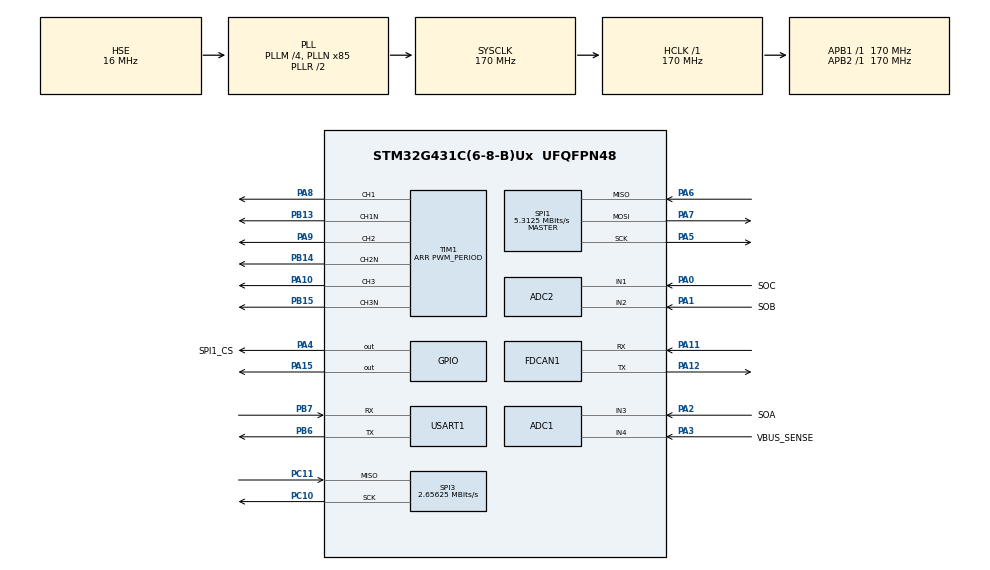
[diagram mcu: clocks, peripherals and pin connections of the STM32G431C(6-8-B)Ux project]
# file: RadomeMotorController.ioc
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ADC1.Channel-0\#ChannelRegularConversion=ADC_CHANNEL_3
ADC1.Channel-1\#ChannelRegularConversion=ADC_CHANNEL_4
ADC1.ClockPrescaler=ADC_CLOCK_ASYNC_DIV1
ADC1.ContinuousConvMode=ENABLE
ADC1.EOCSelection=ADC_EOC_SEQ_CONV
ADC1.ExternalTrigConv=ADC_EXTERNALTRIG_T1_TRGO
ADC1.NbrOfConversion=2
ADC1.NbrOfConversionFlag=1
ADC1.OffsetNumber-0\#ChannelRegularConversion=ADC_OFFSET_NONE
ADC1.OffsetNumber-1\#ChannelRegularConversion=ADC_OFFSET_NONE
ADC1.Overrun=ADC_OVR_DATA_OVERWRITTEN
ADC1.Rank-0\#ChannelRegularConversion=1
ADC1.Rank-1\#ChannelRegularConversion=2
ADC1.SamplingTime-0\#ChannelRegularConversion=ADC_SAMPLETIME_12CYCLES_5
ADC1.SamplingTime-1\#ChannelRegularConversion=ADC_SAMPLETIME_12CYCLES_5
ADC1.master=1
ADC2.Channel-0\#ChannelRegularConversion=ADC_CHANNEL_1
ADC2.Channel-1\#ChannelRegularConversion=ADC_CHANNEL_2
ADC2.ClockPrescaler=ADC_CLOCK_ASYNC_DIV1
ADC2.ContinuousConvMode=ENABLE
ADC2.EOCSelection=ADC_EOC_SEQ_CONV
ADC2.ExternalTrigConv=ADC_EXTERNALTRIG_T1_TRGO
ADC2.NbrOfConversion=2
ADC2.NbrOfConversionFlag=1
ADC2.OffsetNumber-0\#ChannelRegularConversion=ADC_OFFSET_NONE
ADC2.OffsetNumber-1\#ChannelRegularConversion=ADC_OFFSET_NONE
ADC2.Overrun=ADC_OVR_DATA_OVERWRITTEN
ADC2.Rank-0\#ChannelRegularConversion=1
ADC2.Rank-1\#ChannelRegularConversion=2
ADC2.SamplingTime-0\#ChannelRegularConversion=ADC_SAMPLETIME_12CYCLES_5
ADC2.SamplingTime-1\#ChannelRegularConversion=ADC_SAMPLETIME_12CYCLES_5
Dma.ADC1.0.Direction=DMA_PERIPH_TO_MEMORY
Dma.ADC1.0.EventEnable=DISABLE
Dma.ADC1.0.Instance=DMA1_Channel1
Dma.ADC1.0.MemDataAlignment=DMA_MDATAALIGN_HALFWORD
Dma.ADC1.0.MemInc=DMA_MINC_ENABLE
Dma.ADC1.0.Mode=DMA_CIRCULAR
Dma.ADC1.0.PeriphDataAlignment=DMA_PDATAALIGN_HALFWORD
Dma.ADC1.0.PeriphInc=DMA_PINC_DISABLE
Dma.ADC1.0.Polarity=HAL_DMAMUX_REQ_GEN_RISING
Dma.ADC1.0.Priority=DMA_PRIORITY_LOW
Dma.ADC1.0.RequestNumber=1
Dma.ADC1.0.SignalID=NONE
Dma.ADC1.0.SyncEnable=DISABLE
Dma.ADC1.0.SyncPolarity=HAL_DMAMUX_SYNC_NO_EVENT
Dma.ADC1.0.SyncRequestNumber=1
Dma.ADC1.0.SyncSignalID=NONE
Dma.ADC2.1.Direction=DMA_PERIPH_TO_MEMORY
Dma.ADC2.1.EventEnable=DISABLE
Dma.ADC2.1.Instance=DMA1_Channel2
Dma.ADC2.1.MemDataAlignment=DMA_MDATAALIGN_HALFWORD
Dma.ADC2.1.MemInc=DMA_MINC_ENABLE
Dma.ADC2.1.Mode=DMA_CIRCULAR
Dma.ADC2.1.PeriphDataAlignment=DMA_PDATAALIGN_HALFWORD
Dma.ADC2.1.PeriphInc=DMA_PINC_DISABLE
Dma.ADC2.1.Polarity=HAL_DMAMUX_REQ_GEN_RISING
Dma.ADC2.1.Priority=DMA_PRIORITY_LOW
Dma.ADC2.1.RequestNumber=1
Dma.ADC2.1.SignalID=NONE
Dma.ADC2.1.SyncEnable=DISABLE
Dma.ADC2.1.SyncPolarity=HAL_DMAMUX_SYNC_NO_EVENT
Dma.ADC2.1.SyncRequestNumber=1
Dma.ADC2.1.SyncSignalID=NONE
Dma.Request0=ADC1
Dma.Request1=ADC2
Dma.Request2=USART1_RX
Dma.Request3=SPI3_RX
Dma.SPI3_RX.3.Direction=DMA_PERIPH_TO_MEMORY
Dma.SPI3_RX.3.EventEnable=DISABLE
Dma.SPI3_RX.3.Instance=DMA1_Channel4
Dma.SPI3_RX.3.MemDataAlignment=DMA_MDATAALIGN_BYTE
Dma.SPI3_RX.3.MemInc=DMA_MINC_ENABLE
Dma.SPI3_RX.3.Mode=DMA_NORMAL
Dma.SPI3_RX.3.PeriphDataAlignment=DMA_PDATAALIGN_BYTE
Dma.SPI3_RX.3.PeriphInc=DMA_PINC_DISABLE
Dma.SPI3_RX.3.Polarity=HAL_DMAMUX_REQ_GEN_RISING
Dma.SPI3_RX.3.Priority=DMA_PRIORITY_LOW
Dma.SPI3_RX.3.RequestNumber=1
Dma.SPI3_RX.3.SignalID=NONE
Dma.SPI3_RX.3.SyncEnable=DISABLE
Dma.SPI3_RX.3.SyncPolarity=HAL_DMAMUX_SYNC_NO_EVENT
Dma.SPI3_RX.3.SyncRequestNumber=1
Dma.SPI3_RX.3.SyncSignalID=NONE
Dma.USART1_RX.2.Direction=DMA_PERIPH_TO_MEMORY
Dma.USART1_RX.2.EventEnable=DISABLE
Dma.USART1_RX.2.Instance=DMA1_Channel3
Dma.USART1_RX.2.MemDataAlignment=DMA_MDATAALIGN_BYTE
Dma.USART1_RX.2.MemInc=DMA_MINC_ENABLE
Dma.USART1_RX.2.Mode=DMA_CIRCULAR
Dma.USART1_RX.2.PeriphDataAlignment=DMA_PDATAALIGN_BYTE
Dma.USART1_RX.2.PeriphInc=DMA_PINC_DISABLE
Dma.USART1_RX.2.Polarity=HAL_DMAMUX_REQ_GEN_RISING
Dma.USART1_RX.2.Priority=DMA_PRIORITY_LOW
Dma.USART1_RX.2.RequestNumber=1
Dma.USART1_RX.2.SignalID=NONE
Dma.USART1_RX.2.SyncEnable=DISABLE
Dma.USART1_RX.2.SyncPolarity=HAL_DMAMUX_SYNC_NO_EVENT
Dma.USART1_RX.2.SyncRequestNumber=1
Dma.USART1_RX.2.SyncSignalID=NONE
FDCAN1.AutoRetransmission=ENABLE
FDCAN1.CalculateBaudRateNominal=125000
FDCAN1.CalculateTimeBitNominal=8000
FDCAN1.CalculateTimeQuantumNominal=800.0
FDCAN1.ClockDivider=FDCAN_CLOCK_DIV8
FDCAN1.DataPrescaler=17
FDCAN1.DataTimeSeg1=6
FDCAN1.DataTimeSeg2=3
FDCAN1.ExtFiltersNbr=2
FDCAN1.NominalPrescaler=17
FDCAN1.NominalTimeSeg1=6
FDCAN1.NominalTimeSeg2=3
FDCAN1.ProtocolException=ENABLE
FDCAN1.StdFiltersNbr=1
IWDG.Reload=2047
IWDG.Window=2047
Mcu.Family=STM32G4
Mcu.Name=STM32G431C(6-8-B)Ux
Mcu.Package=UFQFPN48
Mcu.UserConstants=ADC_SAMPLES,4;CLOCK_FREQ,170000000;DEAD_TIME,140;ADC_SEQ_LEN,2;PWM_ADC_TRIG,(ADC_CLK_SCALE * ADC_SEQ_LEN * ADC_SAMPLES / 2);PWM_FREQ,20000;ADC_CLK_SCALE,(3 * 25);PWM_PERIOD,(CLOCK_FREQ / (PWM_FREQ * 2));ADC_SW_OFFSET,180
NVIC.ADC1_2_IRQn=true\:0\:0\:false\:false\:true\:true\:true\:true
NVIC.DMA1_Channel1_IRQn=true\:0\:0\:false\:false\:true\:false\:true\:true
NVIC.DMA1_Channel2_IRQn=true\:0\:0\:false\:false\:true\:false\:true\:true
NVIC.DMA1_Channel3_IRQn=true\:0\:0\:false\:false\:true\:false\:true\:true
NVIC.DMA1_Channel4_IRQn=true\:0\:0\:false\:false\:true\:false\:true\:true
NVIC.FDCAN1_IT0_IRQn=true\:3\:0\:true\:false\:true\:true\:true\:true
NVIC.FDCAN1_IT1_IRQn=true\:0\:0\:false\:false\:true\:true\:true\:true
NVIC.PriorityGroup=NVIC_PRIORITYGROUP_4
NVIC.SPI3_IRQn=true\:0\:0\:false\:false\:true\:true\:true\:true
NVIC.TIM1_UP_TIM16_IRQn=true\:2\:0\:true\:false\:true\:true\:true\:true
NVIC.TIM7_IRQn=true\:4\:0\:true\:false\:true\:true\:true\:true
NVIC.USART1_IRQn=true\:7\:0\:true\:false\:true\:true\:true\:true
PA0.GPIO_Label=SOC
PA0.Mode=IN1-Single-Ended
PA0.Signal=ADC2_IN1
PA1.GPIO_Label=SOB
PA1.Mode=IN2-Single-Ended
PA1.Signal=ADC2_IN2
PA10.Signal=S_TIM1_CH3
PA11.Mode=FDCAN_Activate
PA11.Signal=FDCAN1_RX
PA12.Mode=FDCAN_Activate
PA12.Signal=FDCAN1_TX
PA13.Mode=Serial_Wire
PA13.Signal=SYS_JTMS-SWDIO
PA14.Mode=Serial_Wire
PA14.Signal=SYS_JTCK-SWCLK
PA15.Signal=GPIO_Output
PA2.GPIO_Label=SOA
PA2.Mode=IN3-Single-Ended
PA2.Signal=ADC1_IN3
PA3.GPIO_Label=VBUS_SENSE
PA3.Mode=IN4-Single-Ended
PA3.Signal=ADC1_IN4
PA4.GPIO_Label=SPI1_CS
PA4.Signal=GPIO_Output
PA5.Mode=Full_Duplex_Master
PA5.Signal=SPI1_SCK
PA6.Mode=Full_Duplex_Master
PA6.Signal=SPI1_MISO
PA7.Mode=Full_Duplex_Master
PA7.Signal=SPI1_MOSI
PA8.Signal=S_TIM1_CH1
PA9.Signal=S_TIM1_CH2
PB13.Mode=PWM Generation1 CH1 CH1N
PB13.Signal=TIM1_CH1N
PB14.Mode=PWM Generation2 CH2 CH2N
PB14.Signal=TIM1_CH2N
PB15.Mode=PWM Generation3 CH3 CH3N
PB15.Signal=TIM1_CH3N
PB6.Mode=Asynchronous
PB6.Signal=USART1_TX
PB7.Mode=Asynchronous
PB7.Signal=USART1_RX
PC10.Mode=RX_Only_Simplex_Unidirect_Master
PC10.Signal=SPI3_SCK
PC11.Mode=RX_Only_Simplex_Unidirect_Master
PC11.Signal=SPI3_MISO
PF0-OSC_IN.Mode=HSE-External-Oscillator
PF0-OSC_IN.Signal=RCC_OSC_IN
PF1-OSC_OUT.Mode=HSE-External-Oscillator
PF1-OSC_OUT.Signal=RCC_OSC_OUT
ProjectManager.HeapSize=0x200
ProjectManager.StackSize=0x400
ProjectManager.TargetToolchain=STM32CubeIDE
RCC.ADC12CLockSelection=RCC_ADC12CLKSOURCE_PLL
RCC.ADC12Freq_Value=56666666.666666664
RCC.AHBFreq_Value=170000000
RCC.APB1Freq_Value=170000000
RCC.APB1TimFreq_Value=170000000
RCC.APB2Freq_Value=170000000
RCC.APB2TimFreq_Value=170000000
RCC.CK48CLockSelection=RCC_USBCLKSOURCE_HSI48
RCC.CortexFreq_Value=170000000
RCC.EXTERNAL_CLOCK_VALUE=12288000
RCC.HCLKFreq_Value=170000000
RCC.HSE_VALUE=16000000
RCC.HSI48_VALUE=48000000
RCC.HSI_VALUE=16000000
RCC.LSE_VALUE=32768
RCC.PLLM=RCC_PLLM_DIV4
RCC.PLLN=85
RCC.PLLP=RCC_PLLP_DIV6
RCC.PLLQ=RCC_PLLQ_DIV8
RCC.PLLSourceVirtual=RCC_PLLSOURCE_HSE
RCC.PREFETCH_ENABLE=1
RCC.RTCClockSelection=RCC_RTCCLKSOURCE_LSE
RCC.SYSCLKFreq_VALUE=170000000
RCC.SYSCLKSource=RCC_SYSCLKSOURCE_PLLCLK
RCC.USART1CLockSelection=RCC_USART1CLKSOURCE_SYSCLK
RCC.USBFreq_Value=48000000
RCC.VCOOutputFreq_Value=340000000
SH.S_TIM1_CH1.0=TIM1_CH1,PWM Generation1 CH1 CH1N
SH.S_TIM1_CH2.0=TIM1_CH2,PWM Generation2 CH2 CH2N
SH.S_TIM1_CH3.0=TIM1_CH3,PWM Generation3 CH3 CH3N
SPI1.BaudRatePrescaler=SPI_BAUDRATEPRESCALER_32
SPI1.CLKPhase=SPI_PHASE_2EDGE
SPI1.CalculateBaudRate=5.3125 MBits/s
SPI1.DataSize=SPI_DATASIZE_8BIT
SPI1.Direction=SPI_DIRECTION_2LINES
SPI1.Mode=SPI_MODE_MASTER
SPI1.TIMode=SPI_TIMODE_DISABLE
SPI1.VirtualType=VM_MASTER
SPI3.BaudRatePrescaler=SPI_BAUDRATEPRESCALER_64
SPI3.CLKPhase=SPI_PHASE_1EDGE
SPI3.CLKPolarity=SPI_POLARITY_HIGH
SPI3.CalculateBaudRate=2.65625 MBits/s
SPI3.DataSize=SPI_DATASIZE_8BIT
SPI3.Direction=SPI_DIRECTION_2LINES_RXONLY
SPI3.Mode=SPI_MODE_MASTER
SPI3.VirtualType=VM_MASTER
TIM1.Channel-PWM\ Generation1\ CH1\ CH1N=TIM_CHANNEL_1
TIM1.Channel-PWM\ Generation2\ CH2\ CH2N=TIM_CHANNEL_2
TIM1.Channel-PWM\ Generation3\ CH3\ CH3N=TIM_CHANNEL_3
TIM1.Channel-PWM\ Generation4\ No\ Output=TIM_CHANNEL_4
TIM1.CounterMode=TIM_COUNTERMODE_CENTERALIGNED2
TIM1.DeadTime=DEAD_TIME
TIM1.PeriodNoDither=PWM_PERIOD
TIM1.PulseNoDither_1=PWM_PERIOD/2
TIM1.PulseNoDither_2=PWM_PERIOD/2
TIM1.PulseNoDither_3=PWM_PERIOD/2
TIM1.PulseNoDither_4=PWM_ADC_TRIG
TIM1.TIM_MasterOutputTrigger=TIM_TRGO_OC4REF
TIM7.AutoReloadPreload=TIM_AUTORELOAD_PRELOAD_ENABLE
TIM7.PeriodNoDither=499
TIM7.Prescaler=169
TIM7.TIM_MasterOutputTrigger=TIM_TRGO_UPDATE
USART1.VirtualMode-Asynchronous=VM_ASYNC
VP_CORDIC_VS_CORDIC.Mode=CORDIC_Activate
VP_IWDG_VS_IWDG.Mode=IWDG_Activate
VP_SYS_VS_DBSignals.Mode=DisableDeadBatterySignals
VP_TIM1_VS_no_output4.Mode=PWM Generation4 No Output
VP_TIM6_VS_ClockSourceINT.Mode=Enable_Timer
VP_TIM7_VS_ClockSourceINT.Mode=Enable_Timer
board=custom

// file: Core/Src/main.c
/* USER CODE BEGIN Header */
/**
  ******************************************************************************
  * @file           : main.c
  * @brief          : Main program body
  ******************************************************************************
  * @attention
  *
  * Copyright (c) 2022 STMicroelectronics.
  * All rights reserved.
  *
  * This software is licensed under terms that can be found in the LICENSE file
  * in the root directory of this software component.
  * If no LICENSE file comes with this software, it is provided AS-IS.
  *
  ******************************************************************************
  */
/* USER CODE END Header */
#include "main.h"

/* USER CODE BEGIN Includes */
#include <loop.h>

/* USER CODE END Includes */

ADC_HandleTypeDef hadc1;
ADC_HandleTypeDef hadc2;
DMA_HandleTypeDef hdma_adc1;
DMA_HandleTypeDef hdma_adc2;

CORDIC_HandleTypeDef hcordic;

FDCAN_HandleTypeDef hfdcan1;

IWDG_HandleTypeDef hiwdg;

SPI_HandleTypeDef hspi1;
SPI_HandleTypeDef hspi3;
DMA_HandleTypeDef hdma_spi3_rx;

TIM_HandleTypeDef htim1;
TIM_HandleTypeDef htim6;
TIM_HandleTypeDef htim7;

UART_HandleTypeDef huart1;
DMA_HandleTypeDef hdma_usart1_rx;

void SystemClock_Config(void);
static void MX_GPIO_Init(void);
static void MX_DMA_Init(void);
static void MX_ADC2_Init(void);
static void MX_TIM1_Init(void);
static void MX_TIM6_Init(void);
static void MX_ADC1_Init(void);
static void MX_USART1_UART_Init(void);
static void MX_CORDIC_Init(void);
static void MX_FDCAN1_Init(void);
static void MX_SPI3_Init(void);
static void MX_SPI1_Init(void);
static void MX_TIM7_Init(void);
static void MX_IWDG_Init(void);

int main(void)
{

  /* MCU Configuration--------------------------------------------------------*/

  /* Reset of all peripherals, Initializes the Flash interface and the Systick. */
  HAL_Init();

  /* Configure the system clock */
  SystemClock_Config();

  /* Initialize all configured peripherals */
  MX_GPIO_Init();
  MX_DMA_Init();
  MX_TIM1_Init();
  MX_TIM6_Init();
  MX_USART1_UART_Init();
  MX_CORDIC_Init();
  MX_FDCAN1_Init();
  MX_SPI3_Init();
  MX_SPI1_Init();
  MX_TIM7_Init();
  /* USER CODE BEGIN 2 */
  MX_ADC1_Init();
  MX_ADC2_Init();
  setup();

  MX_IWDG_Init();

  /* USER CODE END 2 */

  /* Infinite loop */
  while (1)
  {

    /* USER CODE BEGIN 3 */
	  loop();

  }
  /* USER CODE END 3 */
}

void SystemClock_Config(void)
{
  RCC_OscInitTypeDef RCC_OscInitStruct = {0};
  RCC_ClkInitTypeDef RCC_ClkInitStruct = {0};

  /** Configure the main internal regulator output voltage
  */
  HAL_PWREx_ControlVoltageScaling(PWR_REGULATOR_VOLTAGE_SCALE1_BOOST);

  /** Initializes the RCC Oscillators according to the specified parameters
  * in the RCC_OscInitTypeDef structure.
  */
  RCC_OscInitStruct.OscillatorType = RCC_OSCILLATORTYPE_LSI|RCC_OSCILLATORTYPE_HSE;
  RCC_OscInitStruct.HSEState = RCC_HSE_ON;
  RCC_OscInitStruct.LSIState = RCC_LSI_ON;
  RCC_OscInitStruct.PLL.PLLState = RCC_PLL_ON;
  RCC_OscInitStruct.PLL.PLLSource = RCC_PLLSOURCE_HSE;
  RCC_OscInitStruct.PLL.PLLM = RCC_PLLM_DIV4;
  RCC_OscInitStruct.PLL.PLLN = 85;
  RCC_OscInitStruct.PLL.PLLP = RCC_PLLP_DIV6;
  RCC_OscInitStruct.PLL.PLLQ = RCC_PLLQ_DIV8;
  RCC_OscInitStruct.PLL.PLLR = RCC_PLLR_DIV2;
  if (HAL_RCC_OscConfig(&RCC_OscInitStruct) != HAL_OK)
  {
    Error_Handler();
  }

  /** Initializes the CPU, AHB and APB buses clocks
  */
  RCC_ClkInitStruct.ClockType = RCC_CLOCKTYPE_HCLK|RCC_CLOCKTYPE_SYSCLK
                              |RCC_CLOCKTYPE_PCLK1|RCC_CLOCKTYPE_PCLK2;
  RCC_ClkInitStruct.SYSCLKSource = RCC_SYSCLKSOURCE_PLLCLK;
  RCC_ClkInitStruct.AHBCLKDivider = RCC_SYSCLK_DIV1;
  RCC_ClkInitStruct.APB1CLKDivider = RCC_HCLK_DIV1;
  RCC_ClkInitStruct.APB2CLKDivider = RCC_HCLK_DIV1;

  if (HAL_RCC_ClockConfig(&RCC_ClkInitStruct, FLASH_LATENCY_4) != HAL_OK)
  {
    Error_Handler();
  }
}

static void MX_ADC1_Init(void)
{

  ADC_MultiModeTypeDef multimode = {0};
  ADC_ChannelConfTypeDef sConfig = {0};

  /** Common config
  */
  hadc1.Instance = ADC1;
  hadc1.Init.ClockPrescaler = ADC_CLOCK_ASYNC_DIV1;
  hadc1.Init.Resolution = ADC_RESOLUTION_12B;
  hadc1.Init.DataAlign = ADC_DATAALIGN_RIGHT;
  hadc1.Init.GainCompensation = 0;
  hadc1.Init.ScanConvMode = ADC_SCAN_ENABLE;
  hadc1.Init.EOCSelection = ADC_EOC_SEQ_CONV;
  hadc1.Init.LowPowerAutoWait = DISABLE;
  hadc1.Init.ContinuousConvMode = ENABLE;
  hadc1.Init.NbrOfConversion = 2;
  hadc1.Init.DiscontinuousConvMode = DISABLE;
  hadc1.Init.ExternalTrigConv = ADC_EXTERNALTRIG_T1_TRGO;
  hadc1.Init.ExternalTrigConvEdge = ADC_EXTERNALTRIGCONVEDGE_RISING;
  hadc1.Init.DMAContinuousRequests = DISABLE;
  hadc1.Init.Overrun = ADC_OVR_DATA_OVERWRITTEN;
  hadc1.Init.OversamplingMode = DISABLE;
  if (HAL_ADC_Init(&hadc1) != HAL_OK)
  {
    Error_Handler();
  }

  /** Configure the ADC multi-mode
  */
  multimode.Mode = ADC_MODE_INDEPENDENT;
  if (HAL_ADCEx_MultiModeConfigChannel(&hadc1, &multimode) != HAL_OK)
  {
    Error_Handler();
  }

  /** Configure Regular Channel
  */
  sConfig.Channel = ADC_CHANNEL_3;
  sConfig.Rank = ADC_REGULAR_RANK_1;
  sConfig.SamplingTime = ADC_SAMPLETIME_12CYCLES_5;
  sConfig.SingleDiff = ADC_SINGLE_ENDED;
  sConfig.OffsetNumber = ADC_OFFSET_NONE;
  sConfig.Offset = 0;
  if (HAL_ADC_ConfigChannel(&hadc1, &sConfig) != HAL_OK)
  {
    Error_Handler();
  }

  /** Configure Regular Channel
  */
  sConfig.Channel = ADC_CHANNEL_4;
  sConfig.Rank = ADC_REGULAR_RANK_2;
  if (HAL_ADC_ConfigChannel(&hadc1, &sConfig) != HAL_OK)
  {
    Error_Handler();
  }

}

static void MX_ADC2_Init(void)
{

  ADC_ChannelConfTypeDef sConfig = {0};

  /** Common config
  */
  hadc2.Instance = ADC2;
  hadc2.Init.ClockPrescaler = ADC_CLOCK_ASYNC_DIV1;
  hadc2.Init.Resolution = ADC_RESOLUTION_12B;
  hadc2.Init.DataAlign = ADC_DATAALIGN_RIGHT;
  hadc2.Init.GainCompensation = 0;
  hadc2.Init.ScanConvMode = ADC_SCAN_ENABLE;
  hadc2.Init.EOCSelection = ADC_EOC_SEQ_CONV;
  hadc2.Init.LowPowerAutoWait = DISABLE;
  hadc2.Init.ContinuousConvMode = ENABLE;
  hadc2.Init.NbrOfConversion = 2;
  hadc2.Init.DiscontinuousConvMode = DISABLE;
  hadc2.Init.ExternalTrigConv = ADC_EXTERNALTRIG_T1_TRGO;
  hadc2.Init.ExternalTrigConvEdge = ADC_EXTERNALTRIGCONVEDGE_RISING;
  hadc2.Init.DMAContinuousRequests = DISABLE;
  hadc2.Init.Overrun = ADC_OVR_DATA_OVERWRITTEN;
  hadc2.Init.OversamplingMode = DISABLE;
  if (HAL_ADC_Init(&hadc2) != HAL_OK)
  {
    Error_Handler();
  }

  /** Configure Regular Channel
  */
  sConfig.Channel = ADC_CHANNEL_1;
  sConfig.Rank = ADC_REGULAR_RANK_1;
  sConfig.SamplingTime = ADC_SAMPLETIME_12CYCLES_5;
  sConfig.SingleDiff = ADC_SINGLE_ENDED;
  sConfig.OffsetNumber = ADC_OFFSET_NONE;
  sConfig.Offset = 0;
  if (HAL_ADC_ConfigChannel(&hadc2, &sConfig) != HAL_OK)
  {
    Error_Handler();
  }

  /** Configure Regular Channel
  */
  sConfig.Channel = ADC_CHANNEL_2;
  sConfig.Rank = ADC_REGULAR_RANK_2;
  if (HAL_ADC_ConfigChannel(&hadc2, &sConfig) != HAL_OK)
  {
    Error_Handler();
  }

}

static void MX_CORDIC_Init(void)
{

  hcordic.Instance = CORDIC;
  if (HAL_CORDIC_Init(&hcordic) != HAL_OK)
  {
    Error_Handler();
  }

}

static void MX_FDCAN1_Init(void)
{

  hfdcan1.Instance = FDCAN1;
  hfdcan1.Init.ClockDivider = FDCAN_CLOCK_DIV8;
  hfdcan1.Init.FrameFormat = FDCAN_FRAME_CLASSIC;
  hfdcan1.Init.Mode = FDCAN_MODE_NORMAL;
  hfdcan1.Init.AutoRetransmission = ENABLE;
  hfdcan1.Init.TransmitPause = DISABLE;
  hfdcan1.Init.ProtocolException = ENABLE;
  hfdcan1.Init.NominalPrescaler = 17;
  hfdcan1.Init.NominalSyncJumpWidth = 1;
  hfdcan1.Init.NominalTimeSeg1 = 6;
  hfdcan1.Init.NominalTimeSeg2 = 3;
  hfdcan1.Init.DataPrescaler = 17;
  hfdcan1.Init.DataSyncJumpWidth = 1;
  hfdcan1.Init.DataTimeSeg1 = 6;
  hfdcan1.Init.DataTimeSeg2 = 3;
  hfdcan1.Init.StdFiltersNbr = 1;
  hfdcan1.Init.ExtFiltersNbr = 2;
  hfdcan1.Init.TxFifoQueueMode = FDCAN_TX_FIFO_OPERATION;
  if (HAL_FDCAN_Init(&hfdcan1) != HAL_OK)
  {
    Error_Handler();
  }

}

static void MX_IWDG_Init(void)
{

  hiwdg.Instance = IWDG;
  hiwdg.Init.Prescaler = IWDG_PRESCALER_4;
  hiwdg.Init.Window = 2047;
  hiwdg.Init.Reload = 2047;
  if (HAL_IWDG_Init(&hiwdg) != HAL_OK)
  {
    Error_Handler();
  }

}

static void MX_SPI1_Init(void)
{

  /* SPI1 parameter configuration*/
  hspi1.Instance = SPI1;
  hspi1.Init.Mode = SPI_MODE_MASTER;
  hspi1.Init.Direction = SPI_DIRECTION_2LINES;
  hspi1.Init.DataSize = SPI_DATASIZE_8BIT;
  hspi1.Init.CLKPolarity = SPI_POLARITY_LOW;
  hspi1.Init.CLKPhase = SPI_PHASE_2EDGE;
  hspi1.Init.NSS = SPI_NSS_SOFT;
  hspi1.Init.BaudRatePrescaler = SPI_BAUDRATEPRESCALER_32;
  hspi1.Init.FirstBit = SPI_FIRSTBIT_MSB;
  hspi1.Init.TIMode = SPI_TIMODE_DISABLE;
  hspi1.Init.CRCCalculation = SPI_CRCCALCULATION_DISABLE;
  hspi1.Init.CRCPolynomial = 7;
  hspi1.Init.CRCLength = SPI_CRC_LENGTH_DATASIZE;
  hspi1.Init.NSSPMode = SPI_NSS_PULSE_DISABLE;
  if (HAL_SPI_Init(&hspi1) != HAL_OK)
  {
    Error_Handler();
  }

}

static void MX_SPI3_Init(void)
{

  /* SPI3 parameter configuration*/
  hspi3.Instance = SPI3;
  hspi3.Init.Mode = SPI_MODE_MASTER;
  hspi3.Init.Direction = SPI_DIRECTION_2LINES_RXONLY;
  hspi3.Init.DataSize = SPI_DATASIZE_8BIT;
  hspi3.Init.CLKPolarity = SPI_POLARITY_HIGH;
  hspi3.Init.CLKPhase = SPI_PHASE_1EDGE;
  hspi3.Init.NSS = SPI_NSS_SOFT;
  hspi3.Init.BaudRatePrescaler = SPI_BAUDRATEPRESCALER_64;
  hspi3.Init.FirstBit = SPI_FIRSTBIT_MSB;
  hspi3.Init.TIMode = SPI_TIMODE_DISABLE;
  hspi3.Init.CRCCalculation = SPI_CRCCALCULATION_DISABLE;
  hspi3.Init.CRCPolynomial = 7;
  hspi3.Init.CRCLength = SPI_CRC_LENGTH_DATASIZE;
  hspi3.Init.NSSPMode = SPI_NSS_PULSE_ENABLE;
  if (HAL_SPI_Init(&hspi3) != HAL_OK)
  {
    Error_Handler();
  }

}

static void MX_TIM1_Init(void)
{

  TIM_MasterConfigTypeDef sMasterConfig = {0};
  TIM_OC_InitTypeDef sConfigOC = {0};
  TIM_BreakDeadTimeConfigTypeDef sBreakDeadTimeConfig = {0};

  htim1.Instance = TIM1;
  htim1.Init.Prescaler = 0;
  htim1.Init.CounterMode = TIM_COUNTERMODE_CENTERALIGNED2;
  htim1.Init.Period = 4250;
  htim1.Init.ClockDivision = TIM_CLOCKDIVISION_DIV1;
  htim1.Init.RepetitionCounter = 0;
  htim1.Init.AutoReloadPreload = TIM_AUTORELOAD_PRELOAD_DISABLE;
  if (HAL_TIM_PWM_Init(&htim1) != HAL_OK)
  {
    Error_Handler();
  }
  sMasterConfig.MasterOutputTrigger = TIM_TRGO_OC4REF;
  sMasterConfig.MasterOutputTrigger2 = TIM_TRGO2_RESET;
  sMasterConfig.MasterSlaveMode = TIM_MASTERSLAVEMODE_DISABLE;
  if (HAL_TIMEx_MasterConfigSynchronization(&htim1, &sMasterConfig) != HAL_OK)
  {
    Error_Handler();
  }
  sConfigOC.OCMode = TIM_OCMODE_PWM1;
  sConfigOC.Pulse = 2125;
  sConfigOC.OCPolarity = TIM_OCPOLARITY_HIGH;
  sConfigOC.OCNPolarity = TIM_OCNPOLARITY_HIGH;
  sConfigOC.OCFastMode = TIM_OCFAST_DISABLE;
  sConfigOC.OCIdleState = TIM_OCIDLESTATE_RESET;
  sConfigOC.OCNIdleState = TIM_OCNIDLESTATE_RESET;
  if (HAL_TIM_PWM_ConfigChannel(&htim1, &sConfigOC, TIM_CHANNEL_1) != HAL_OK)
  {
    Error_Handler();
  }
  if (HAL_TIM_PWM_ConfigChannel(&htim1, &sConfigOC, TIM_CHANNEL_2) != HAL_OK)
  {
    Error_Handler();
  }
  if (HAL_TIM_PWM_ConfigChannel(&htim1, &sConfigOC, TIM_CHANNEL_3) != HAL_OK)
  {
    Error_Handler();
  }
  sConfigOC.Pulse = 300;
  if (HAL_TIM_PWM_ConfigChannel(&htim1, &sConfigOC, TIM_CHANNEL_4) != HAL_OK)
  {
    Error_Handler();
  }
  sBreakDeadTimeConfig.OffStateRunMode = TIM_OSSR_DISABLE;
  sBreakDeadTimeConfig.OffStateIDLEMode = TIM_OSSI_DISABLE;
  sBreakDeadTimeConfig.LockLevel = TIM_LOCKLEVEL_OFF;
  sBreakDeadTimeConfig.DeadTime = DEAD_TIME;
  sBreakDeadTimeConfig.BreakState = TIM_BREAK_DISABLE;
  sBreakDeadTimeConfig.BreakPolarity = TIM_BREAKPOLARITY_HIGH;
  sBreakDeadTimeConfig.BreakFilter = 0;
  sBreakDeadTimeConfig.BreakAFMode = TIM_BREAK_AFMODE_INPUT;
  sBreakDeadTimeConfig.Break2State = TIM_BREAK2_DISABLE;
  sBreakDeadTimeConfig.Break2Polarity = TIM_BREAK2POLARITY_HIGH;
  sBreakDeadTimeConfig.Break2Filter = 0;
  sBreakDeadTimeConfig.Break2AFMode = TIM_BREAK_AFMODE_INPUT;
  sBreakDeadTimeConfig.AutomaticOutput = TIM_AUTOMATICOUTPUT_DISABLE;
  if (HAL_TIMEx_ConfigBreakDeadTime(&htim1, &sBreakDeadTimeConfig) != HAL_OK)
  {
    Error_Handler();
  }
  HAL_TIM_MspPostInit(&htim1);

}

static void MX_TIM6_Init(void)
{

  TIM_MasterConfigTypeDef sMasterConfig = {0};

  htim6.Instance = TIM6;
  htim6.Init.Prescaler = 0;
  htim6.Init.CounterMode = TIM_COUNTERMODE_UP;
  htim6.Init.Period = 65535;
  htim6.Init.AutoReloadPreload = TIM_AUTORELOAD_PRELOAD_DISABLE;
  if (HAL_TIM_Base_Init(&htim6) != HAL_OK)
  {
    Error_Handler();
  }
  sMasterConfig.MasterOutputTrigger = TIM_TRGO_RESET;
  sMasterConfig.MasterSlaveMode = TIM_MASTERSLAVEMODE_DISABLE;
  if (HAL_TIMEx_MasterConfigSynchronization(&htim6, &sMasterConfig) != HAL_OK)
  {
    Error_Handler();
  }

}

static void MX_TIM7_Init(void)
{

  TIM_MasterConfigTypeDef sMasterConfig = {0};

  htim7.Instance = TIM7;
  htim7.Init.Prescaler = 169;
  htim7.Init.CounterMode = TIM_COUNTERMODE_UP;
  htim7.Init.Period = 499;
  htim7.Init.AutoReloadPreload = TIM_AUTORELOAD_PRELOAD_ENABLE;
  if (HAL_TIM_Base_Init(&htim7) != HAL_OK)
  {
    Error_Handler();
  }
  sMasterConfig.MasterOutputTrigger = TIM_TRGO_UPDATE;
  sMasterConfig.MasterSlaveMode = TIM_MASTERSLAVEMODE_DISABLE;
  if (HAL_TIMEx_MasterConfigSynchronization(&htim7, &sMasterConfig) != HAL_OK)
  {
    Error_Handler();
  }

}

static void MX_USART1_UART_Init(void)
{

  huart1.Instance = USART1;
  huart1.Init.BaudRate = 115200;
  huart1.Init.WordLength = UART_WORDLENGTH_8B;
  huart1.Init.StopBits = UART_STOPBITS_1;
  huart1.Init.Parity = UART_PARITY_NONE;
  huart1.Init.Mode = UART_MODE_TX_RX;
  huart1.Init.HwFlowCtl = UART_HWCONTROL_NONE;
  huart1.Init.OverSampling = UART_OVERSAMPLING_16;
  huart1.Init.OneBitSampling = UART_ONE_BIT_SAMPLE_DISABLE;
  huart1.Init.ClockPrescaler = UART_PRESCALER_DIV1;
  huart1.AdvancedInit.AdvFeatureInit = UART_ADVFEATURE_NO_INIT;
  if (HAL_UART_Init(&huart1) != HAL_OK)
  {
    Error_Handler();
  }
  if (HAL_UARTEx_SetTxFifoThreshold(&huart1, UART_TXFIFO_THRESHOLD_1_8) != HAL_OK)
  {
    Error_Handler();
  }
  if (HAL_UARTEx_SetRxFifoThreshold(&huart1, UART_RXFIFO_THRESHOLD_1_8) != HAL_OK)
  {
    Error_Handler();
  }
  if (HAL_UARTEx_DisableFifoMode(&huart1) != HAL_OK)
  {
    Error_Handler();
  }

}

static void MX_DMA_Init(void)
{

  /* DMA controller clock enable */
  __HAL_RCC_DMAMUX1_CLK_ENABLE();
  __HAL_RCC_DMA1_CLK_ENABLE();

  /* DMA interrupt init */
  /* DMA1_Channel1_IRQn interrupt configuration */
  HAL_NVIC_SetPriority(DMA1_Channel1_IRQn, 0, 0);
  HAL_NVIC_EnableIRQ(DMA1_Channel1_IRQn);
  /* DMA1_Channel2_IRQn interrupt configuration */
  HAL_NVIC_SetPriority(DMA1_Channel2_IRQn, 0, 0);
  HAL_NVIC_EnableIRQ(DMA1_Channel2_IRQn);
  /* DMA1_Channel3_IRQn interrupt configuration */
  HAL_NVIC_SetPriority(DMA1_Channel3_IRQn, 0, 0);
  HAL_NVIC_EnableIRQ(DMA1_Channel3_IRQn);
  /* DMA1_Channel4_IRQn interrupt configuration */
  HAL_NVIC_SetPriority(DMA1_Channel4_IRQn, 0, 0);
  HAL_NVIC_EnableIRQ(DMA1_Channel4_IRQn);

}

static void MX_GPIO_Init(void)
{
  GPIO_InitTypeDef GPIO_InitStruct = {0};

  /* GPIO Ports Clock Enable */
  __HAL_RCC_GPIOF_CLK_ENABLE();
  __HAL_RCC_GPIOA_CLK_ENABLE();
  __HAL_RCC_GPIOB_CLK_ENABLE();
  __HAL_RCC_GPIOC_CLK_ENABLE();

  /*Configure GPIO pin Output Level */
  HAL_GPIO_WritePin(GPIOA, SPI1_CS_Pin|GPIO_PIN_15, GPIO_PIN_RESET);

  /*Configure GPIO pins : SPI1_CS_Pin PA15 */
  GPIO_InitStruct.Pin = SPI1_CS_Pin|GPIO_PIN_15;
  GPIO_InitStruct.Mode = GPIO_MODE_OUTPUT_PP;
  GPIO_InitStruct.Pull = GPIO_NOPULL;
  GPIO_InitStruct.Speed = GPIO_SPEED_FREQ_LOW;
  HAL_GPIO_Init(GPIOA, &GPIO_InitStruct);

}

void Error_Handler(void)
{
  __disable_irq();
  while (1)
  {
  }
}
